# PIC32MK0512GPD100 device description
Architecture: MIPS; Family: PIC32MK; Series: PIC32MK
Registers are 32-bit, read-write, no defined reset value unless marked. A register's access mark holds for its fields unless they carry their own. Offsets are from the block's base; [hi:lo] are bit positions; {n}, {i} and the like mark numbered series; 'fields as' and 'values as' point back to an identical list; <NAME> marks a mode.

## CMP
Instances: CMP 0x1f82c000 in periph_pb2_std
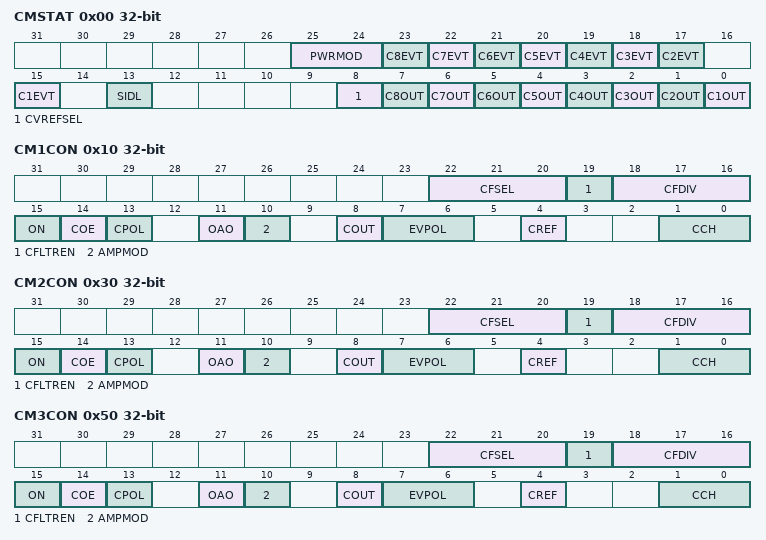
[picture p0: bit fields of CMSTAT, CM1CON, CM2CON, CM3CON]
0x00 CMSTAT — Op amp/Comparator Status Register
  [25:24] PWRMOD
  [n+15] C{n}EVT (n=2..8)
  [15] C1EVT
  [13] SIDL — Stop in Idle Mode bit
    1=Discontinue operation of all Op amp/Comparators when device enters Idle mode; 0=Continue module operation in Idle mode
  [8] CVREFSEL
  [7] C8OUT
  [6] C7OUT
  [5] C6OUT
  [n-1] C{n}OUT (n=1..5) — Op amp/Comparator {n} Output Status bit
    1=(When CPOL is 0) Vin+ > Vth+ / (When CPOL is 1) VIN+ Vth+ / (When CPOL is 1) VIN+ < VTH-; 0=(When CPOL is 0) VIN+ VTH+
0x10 CM1CON — Op amp/Comparator 'x' Control Register ('x' = 1-5)
  [22:20] CFSEL — Comparator Output Filter Clock Source Select bits
    {v}=PBCLK2/Timer{v-2} Period Value (PR{v-2}) (v=4..7); 3=REFCLK3 Clock; 2=PWM Secondary Special Event; 1=PPBCLK2 Clock; 0=SYSCLK Clock
  [19] CFLTREN — Comparator Output Digital Filter Enable bit
    1=Digital Filters enabled; 0=Digital Filters disabled
  [18:16] CFDIV — Comparator Output Filter Clock Divide Select bits
    7=1:128 Clock Divide; 6=1:64 Clock Divide; 5=1:32 Clock Divide; 4=1:16 Clock Divide; 3=1:8 Clock Divide; 2=1:4 Clock Divide; 1=1:2 Clock Divide; 0=1:1 Clock Divide
  [15] ON — Comparator Enable bit
    1=Comparator is enabled; 0=Comparator is disabled
  [14] COE — Comparator Output Enable bit
    1=Comparator output is present on the CxOUT pin; 0=Comparator output is internal only
  [13] CPOL — Comparator Output Polarity Select bit
    1=Comparator output is inverted; 0=Comparator output is not inverted
  [11] OAO — Op amp Output Enable bit
    1=Op amp output is present on the OAxOUT pin; 0=Op amp output is not present on the OAxOUT pin
  [10] AMPMOD — Op amp Mode Enable bit
    1=Amplifier/Comparator operating in Dual mode (both Op amps and Comparators are enabled); 0=Amplifier/Comparator operating in Comparator-only mode
  [8] COUT — Comparator Output bit
    1=(When CPOL is 0)VIN+ > VTH+ / (When CPOL is 1) VIN+ VTH+ / (When CPOL is 1) VIN+ < VTH-; 0=(When CPOL is 0)VIN+ VTH+
  [7:6] EVPOL — Trigger/Event Polarity Select bits
    3=Trigger/Event generated on any change of the comparator output; 2=(If CPOL is 0) High-to-low transition of the comparator output / (If CPOL is 1) Low-to-high transition of the comparator output; 1=(If CPOL is 0) Low-to-high transition of the comparator output / (If CPOL is 1) High-to-low transition of the comparator output; 0=Trigger/Event generation is disabled
  [4] CREF — Op amp/Comparator Reference Select bit
    1=VIN+ input connects to internal CDAC3 output voltage; 0=VIN+ input connects to CxIN1+ pin
  [1:0] CCH — Comparator Channel Select bits
    {v}=CxIN{v+1}- (v=0..3)
0x30 CM2CON — Op amp/Comparator 'x' Control Register ('x' = 1-5)
  fields as CM1CON
0x50 CM3CON — Op amp/Comparator 'x' Control Register ('x' = 1-5)
  fields as CM1CON
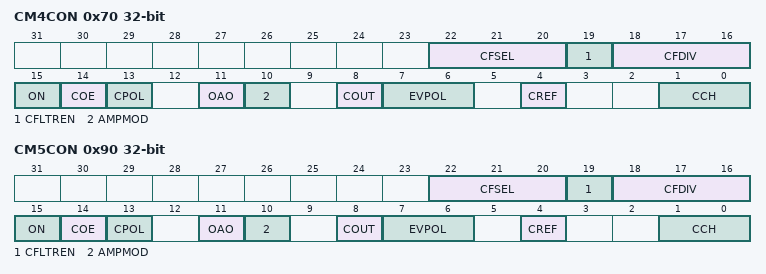
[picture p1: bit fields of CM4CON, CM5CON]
0x70 CM4CON — Op amp/Comparator 'x' Control Register ('x' = 1-5)
  fields as CM1CON
0x90 CM5CON — Op amp/Comparator 'x' Control Register ('x' = 1-5)
  fields as CM1CON

## RCON — Reset Controller
Instances: RCON 0x1f801200 in periph_pb1_std
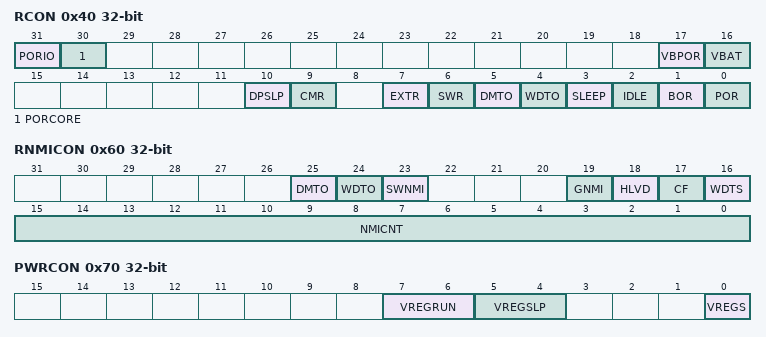
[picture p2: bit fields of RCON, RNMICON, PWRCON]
0x40 RCON — Reset Control Register
  [31] PORIO — I/O Voltage POR Flag bit
    1=A Power-up Reset has occurred due to I/O Voltage; 0=A Power-up Reset has not occurred due to I/O Voltage
  [30] PORCORE — Core Voltage POR Flag bit
    1=A Power-up Reset has occurred due to Core Voltage; 0=A Power-up Reset has not occurred due to Core Voltage
  [17] VBPOR — VBPOR Mode Flag bit
    1=A VBAT domain POR has occurred; 0=A VBAT domain POR has not occurred
  [16] VBAT — VBAT Mode Flag bit
    1=A POR exit from VBAT has occurred (a true POR must be established with the valid VBAT voltage on the VBAT pin); 0=A POR exit from VBAT has not occurred
  [10] DPSLP — Deep Sleep Mode Flag bit
    1=Deep Sleep mode has occurred; 0=Deep Sleep mode has not occurred
  [9] CMR — Configuration Mismatch Reset Flag bit
    1=A Configuration Mismatch Reset has occurred; 0=A Configuration Mismatch Reset has not occurred
  [7] EXTR — External Reset (MCLR) Pin Flag bit
    1=Master Clear (pin) Reset has occurred; 0=Master Clear (pin) Reset has not occurred
  [6] SWR — Software Reset Flag bit
    1=Software Reset was executed; 0=Software Reset was not executed
  [5] DMTO — Deadman Timer Time-out Flag bit
    1=A DMT time-out has occurred; 0=A DMT time-out has not occurred
  [4] WDTO — Watchdog Timer Time-out Flag bit
    1=WDT Time-out has occurred; 0=WDT Time-out has not occurred
  [3] SLEEP — Wake From Sleep Flag bit
    1=Device was in Sleep mode; 0=Device was not in Sleep mode
  [2] IDLE — Wake From Idle Flag bit
    1=Device was in Idle mode; 0=Device was not in Idle mode
  [1] BOR — Brown-out Reset Flag bit
    1=Brown-out Reset has occurred; 0=Brown-out Reset has not occurred
  [0] POR — Power-on Reset Flag bit
    1=Power-on Reset has occurred; 0=Power-on Reset has not occurred
0x50 RSWRST wo — Software Reset Register
  [0] SWRST — Software Reset Trigger bit
    1=Enable software Reset event; 0=No effect
0x60 RNMICON — Non-Maskable Interrupt (NMI) Control Register
  [25] DMTO — Deadman Timer Time-out Flag bit
    1=DMT time-out has occurred and caused a NMI; 0=DMT time-out has not occurred
  [24] WDTO — Watchdog Timer Time-Out Flag bit
    1=WDT time-out has occurred and caused a NMI; 0=WDT time-out has not occurred
  [23] SWNMI — Software NMI Trigger.
    1=An NMI will be generated; 0=An NMI will not be generated
  [19] GNMI — General NMI bit
    1=A general NMI event has been detected or a user-initiated NMI event has occurred; 0=A general NMI event has not been detected
  [18] HLVD
  [17] CF — Clock Fail Detect bit
    1=FSCM has detected clock failure and caused an NMI; 0=FSCM has not detected clock failure
  [16] WDTS — Watchdog Timer Time-out in Sleep Mode Flag bit (Setting this bit will cause a WDT NMI)
    1=WDT time-out has occurred during Sleep mode and caused a wake-up from sleep; 0=WDT time-out has not occurred during Sleep mode
  [15:0] NMICNT — NMI Reset Counter Value bits
    255=255 SYSCLK cycles before a device Reset occurs; 254=254 SYSCLK cycles before a device Reset occurs; 1=1 SYSCLK cycle before a device Reset occurs; 0=No delay between NMI assertion and device Reset event
0x70 PWRCON — Power Control Register
  [7:6] VREGRUN
  [5:4] VREGSLP
  [0] VREGS — Internal Voltage Regulator Stand-by Enable bit
    1=Voltage regulator will remain active during Sleep; 0=Voltage regulator will go to Stand-by mode during Sleep

## Notices in the file
Copyright (c) 2017 Microchip Technology Inc.
SPDX-License-Identifier: Apache-2.0
Licensed under the Apache License, Version 2.0 (the "License");
you may not use this file except in compliance with the License.
You may obtain a copy of the License at
http://www.apache.org/licenses/LICENSE-2.0
Unless required by applicable law or agreed to in writing, software
distributed under the License is distributed on an "AS IS" BASIS,
WITHOUT WARRANTIES OR CONDITIONS OF ANY KIND, either express or implied.
See the License for the specific language governing permissions and
limitations under the License.
